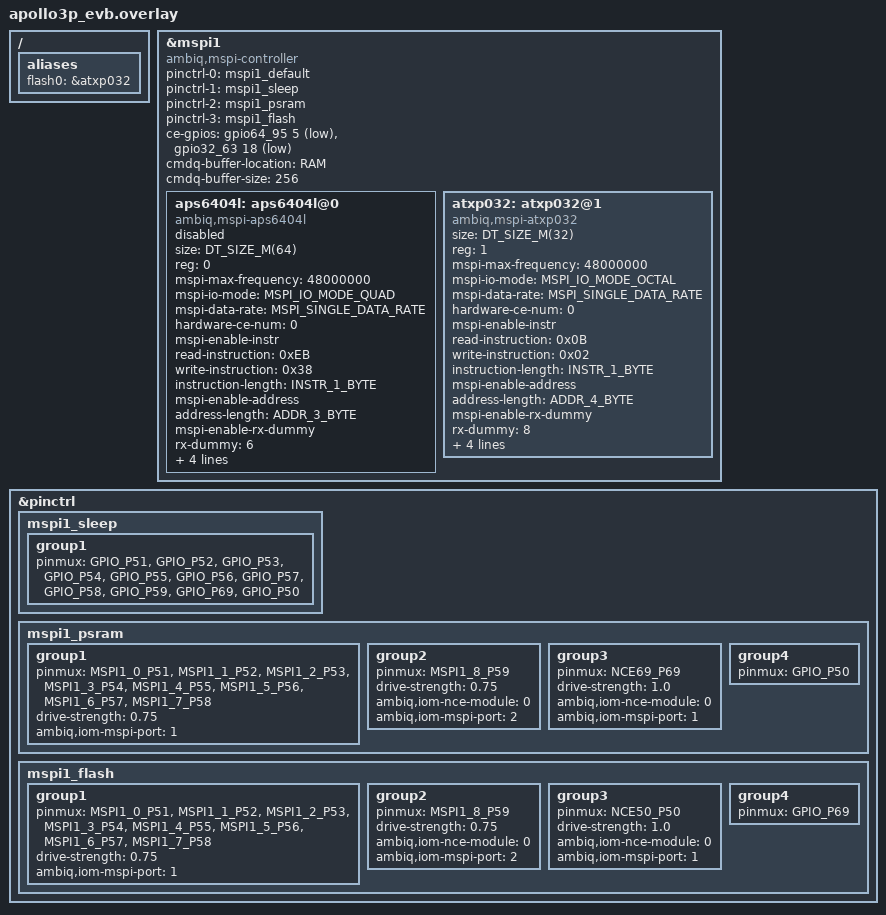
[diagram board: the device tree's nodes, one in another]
/*
 * Copyright (c) 2024 Ambiq Inc.
 *
 * SPDX-License-Identifier: Apache-2.0
 */

/ {
    aliases {
        flash0 = &atxp032;
    };
};

&mspi1 {
    compatible = "ambiq,mspi-controller";
    pinctrl-0 = <&mspi1_default>;
    pinctrl-1 = <&mspi1_sleep>;
    pinctrl-2 = <&mspi1_psram>;
    pinctrl-3 = <&mspi1_flash>;
    pinctrl-names = "default","sleep","psram","flash";
    status = "okay";

    ce-gpios = <&gpio64_95 5 GPIO_ACTIVE_LOW>,
               <&gpio32_63 18 GPIO_ACTIVE_LOW>;

    cmdq-buffer-location = "RAM";
    cmdq-buffer-size = <256>;

    aps6404l: aps6404l@0 {
        compatible = "ambiq,mspi-aps6404l";
        size = <DT_SIZE_M(64)>;
        reg = <0>;
        status = "disabled";
        mspi-max-frequency = <48000000>;
        mspi-io-mode = "MSPI_IO_MODE_QUAD";
        mspi-data-rate = "MSPI_SINGLE_DATA_RATE";
        hardware-ce-num = <0>;
        mspi-enable-instr;
        read-instruction = <0xEB>;
        write-instruction = <0x38>;
        instruction-length = "INSTR_1_BYTE";
        mspi-enable-address;
        address-length = "ADDR_3_BYTE";
        mspi-enable-rx-dummy;
        rx-dummy = <6>;
        tx-dummy = <0>;
        xip-config = <1 0 0 0>;
        ce-break-config = <0x6 30>;
        timing-config = <1 1 0 1 0 6>;
    };
    atxp032: atxp032@1 {
        compatible = "ambiq,mspi-atxp032";
        size = <DT_SIZE_M(32)>;
        reg = <1>;
        status = "okay";
        mspi-max-frequency = <48000000>;
        mspi-io-mode = "MSPI_IO_MODE_OCTAL";
        mspi-data-rate = "MSPI_SINGLE_DATA_RATE";
        hardware-ce-num = <0>;
        mspi-enable-instr;
        read-instruction = <0x0B>;
        write-instruction = <0x02>;
        instruction-length = "INSTR_1_BYTE";
        mspi-enable-address;
        address-length = "ADDR_4_BYTE";
        mspi-enable-rx-dummy;
        rx-dummy = <8>;
        tx-dummy = <0>;
        xip-config = <1 0 0 0>;
        ce-break-config = <0 0>;
        timing-config = <1 1 0 1 0 8>;
    };
};

&pinctrl {
    mspi1_sleep: mspi1_sleep{
		group1 {
			pinmux = <GPIO_P51>,
				 <GPIO_P52>,
				 <GPIO_P53>,
				 <GPIO_P54>,
				 <GPIO_P55>,
				 <GPIO_P56>,
				 <GPIO_P57>,
				 <GPIO_P58>,
                 <GPIO_P59>,
                 <GPIO_P69>,
                 <GPIO_P50>;
		};
    };
    mspi1_psram: mspi1_psram{
		group1 {
			pinmux = <MSPI1_0_P51>,
				 <MSPI1_1_P52>,
				 <MSPI1_2_P53>,
				 <MSPI1_3_P54>,
				 <MSPI1_4_P55>,
				 <MSPI1_5_P56>,
				 <MSPI1_6_P57>,
				 <MSPI1_7_P58>;
            drive-strength = "0.75";
            ambiq,iom-mspi-port = <1>;
		};
        group2 {
            pinmux = <MSPI1_8_P59>;
            drive-strength = "0.75";
            ambiq,iom-nce-module = <0>;
            ambiq,iom-mspi-port = <2>;
        };
		group3 {
			pinmux = <NCE69_P69>;
			drive-strength = "1.0";
			ambiq,iom-nce-module = <0>;
            ambiq,iom-mspi-port = <1>;
		};
        group4 {
            pinmux = <GPIO_P50>;
        };
	};
    mspi1_flash: mspi1_flash{
		group1 {
			pinmux = <MSPI1_0_P51>,
				 <MSPI1_1_P52>,
				 <MSPI1_2_P53>,
				 <MSPI1_3_P54>,
				 <MSPI1_4_P55>,
				 <MSPI1_5_P56>,
				 <MSPI1_6_P57>,
				 <MSPI1_7_P58>;
            drive-strength = "0.75";
            ambiq,iom-mspi-port = <1>;
		};
        group2 {
            pinmux = <MSPI1_8_P59>;
            drive-strength = "0.75";
            ambiq,iom-nce-module = <0>;
            ambiq,iom-mspi-port = <2>;
        };
		group3 {
			pinmux = <NCE50_P50>;
			drive-strength = "1.0";
			ambiq,iom-nce-module = <0>;
            ambiq,iom-mspi-port = <1>;
		};
        group4 {
            pinmux = <GPIO_P69>;
        };
	};
};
